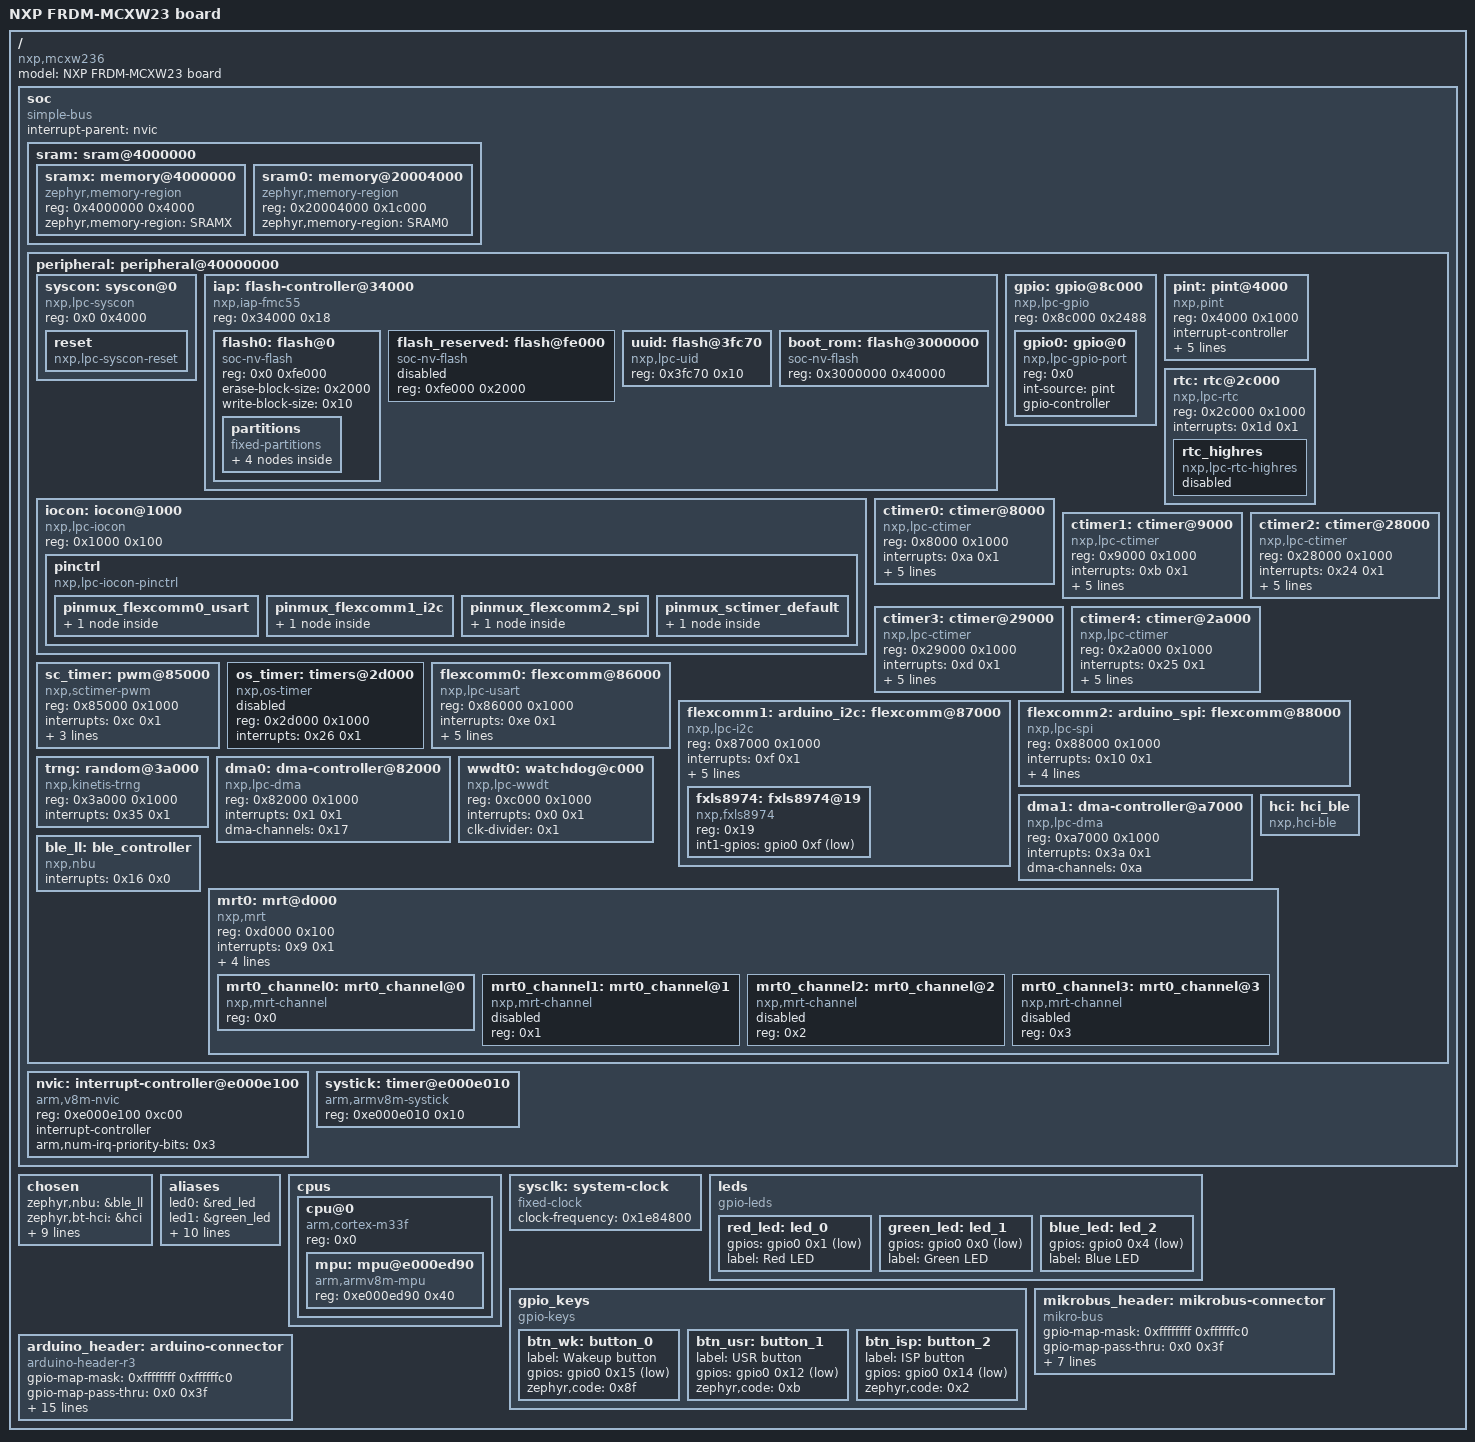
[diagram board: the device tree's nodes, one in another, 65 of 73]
/dts-v1/;

/* node '/' defined in zephyr/dts/arm/nxp/nxp_mcxw236_ns.dtsi:7 */
/ {
	#address-cells = < 0x1 >;        /* in zephyr/dts/common/skeleton.dtsi:10 */
	#size-cells = < 0x1 >;           /* in zephyr/dts/common/skeleton.dtsi:11 */
	model = "NXP FRDM-MCXW23 board"; /* in zephyr/boards/nxp/frdm_mcxw23/frdm_mcxw23.dts:13 */
	compatible = "nxp,mcxw236",
	             "nxp,mcx";          /* in zephyr/boards/nxp/frdm_mcxw23/frdm_mcxw23.dts:14 */

	/* node '/soc' defined in zephyr/dts/arm/nxp/nxp_mcxw236_ns.dtsi:8 */
	soc {
		#address-cells = < 0x1 >;     /* in zephyr/dts/arm/armv8-m.dtsi:7 */
		#size-cells = < 0x1 >;        /* in zephyr/dts/arm/armv8-m.dtsi:8 */
		compatible = "simple-bus";    /* in zephyr/dts/arm/armv8-m.dtsi:9 */
		interrupt-parent = < &nvic >; /* in zephyr/dts/arm/armv8-m.dtsi:10 */
		ranges;                       /* in zephyr/dts/arm/armv8-m.dtsi:11 */

		/* node '/soc/sram@4000000' defined in zephyr/dts/arm/nxp/nxp_mcxw236_ns.dtsi:9 */
		sram: sram@4000000 {
			ranges = < 0x4000000 0x4000000 0x20004000 >; /* in zephyr/dts/arm/nxp/nxp_mcxw236_ns.dtsi:10 */
			#address-cells = < 0x1 >;                    /* in zephyr/dts/arm/nxp/nxp_mcxw23x_common.dtsi:51 */
			#size-cells = < 0x1 >;                       /* in zephyr/dts/arm/nxp/nxp_mcxw23x_common.dtsi:52 */

			/* node '/soc/sram@4000000/memory@4000000' defined in zephyr/dts/arm/nxp/nxp_mcxw23x_common.dtsi:54 */
			sramx: memory@4000000 {
				compatible = "zephyr,memory-region",
				             "mmio-sram";            /* in zephyr/dts/arm/nxp/nxp_mcxw23x_common.dtsi:55 */
				reg = < 0x4000000 0x4000 >;          /* in zephyr/dts/arm/nxp/nxp_mcxw23x_common.dtsi:56 */
				zephyr,memory-region = "SRAMX";      /* in zephyr/dts/arm/nxp/nxp_mcxw23x_common.dtsi:57 */
			};

			/* node '/soc/sram@4000000/memory@20004000' defined in zephyr/dts/arm/nxp/nxp_mcxw23x_common.dtsi:60 */
			sram0: memory@20004000 {
				compatible = "zephyr,memory-region",
				             "mmio-sram";            /* in zephyr/dts/arm/nxp/nxp_mcxw23x_common.dtsi:61 */
				reg = < 0x20004000 0x1c000 >;        /* in zephyr/dts/arm/nxp/nxp_mcxw23x_common.dtsi:62 */
				zephyr,memory-region = "SRAM0";      /* in zephyr/dts/arm/nxp/nxp_mcxw23x_common.dtsi:63 */
			};
		};

		/* node '/soc/peripheral@40000000' defined in zephyr/dts/arm/nxp/nxp_mcxw236_ns.dtsi:13 */
		peripheral: peripheral@40000000 {
			ranges = < 0x0 0x40000000 0x10000000 >; /* in zephyr/dts/arm/nxp/nxp_mcxw236_ns.dtsi:14 */
			#address-cells = < 0x1 >;               /* in zephyr/dts/arm/nxp/nxp_mcxw23x_common.dtsi:72 */
			#size-cells = < 0x1 >;                  /* in zephyr/dts/arm/nxp/nxp_mcxw23x_common.dtsi:73 */

			/* node '/soc/peripheral@40000000/syscon@0' defined in zephyr/dts/arm/nxp/nxp_mcxw23x_common.dtsi:75 */
			syscon: syscon@0 {
				compatible = "nxp,lpc-syscon"; /* in zephyr/dts/arm/nxp/nxp_mcxw23x_common.dtsi:76 */
				reg = < 0x0 0x4000 >;          /* in zephyr/dts/arm/nxp/nxp_mcxw23x_common.dtsi:77 */
				#clock-cells = < 0x1 >;        /* in zephyr/dts/arm/nxp/nxp_mcxw23x_common.dtsi:78 */
				phandle = < 0x2 >;             /* in zephyr/dts/arm/nxp/nxp_mcxw23x_common.dtsi:174 */

				/* node '/soc/peripheral@40000000/syscon@0/reset' defined in zephyr/dts/arm/nxp/nxp_mcxw23x_common.dtsi:80 */
				reset: reset {
					compatible = "nxp,lpc-syscon-reset"; /* in zephyr/dts/arm/nxp/nxp_mcxw23x_common.dtsi:81 */
					#reset-cells = < 0x1 >;              /* in zephyr/dts/arm/nxp/nxp_mcxw23x_common.dtsi:82 */
					phandle = < 0x4 >;                   /* in zephyr/dts/arm/nxp/nxp_mcxw23x_common.dtsi:250 */
				};
			};

			/* node '/soc/peripheral@40000000/flash-controller@34000' defined in zephyr/dts/arm/nxp/nxp_mcxw23x_common.dtsi:86 */
			iap: flash-controller@34000 {
				compatible = "nxp,iap-fmc55"; /* in zephyr/dts/arm/nxp/nxp_mcxw23x_common.dtsi:87 */
				reg = < 0x34000 0x18 >;       /* in zephyr/dts/arm/nxp/nxp_mcxw23x_common.dtsi:88 */
				#address-cells = < 0x1 >;     /* in zephyr/dts/arm/nxp/nxp_mcxw23x_common.dtsi:89 */
				#size-cells = < 0x1 >;        /* in zephyr/dts/arm/nxp/nxp_mcxw23x_common.dtsi:90 */
				status = "okay";              /* in zephyr/dts/arm/nxp/nxp_mcxw23x_common.dtsi:91 */

				/* node '/soc/peripheral@40000000/flash-controller@34000/flash@0' defined in zephyr/dts/arm/nxp/nxp_mcxw23x_common.dtsi:93 */
				flash0: flash@0 {
					compatible = "soc-nv-flash";   /* in zephyr/dts/arm/nxp/nxp_mcxw23x_common.dtsi:94 */
					reg = < 0x0 0xfe000 >;         /* in zephyr/dts/arm/nxp/nxp_mcxw23x_common.dtsi:95 */
					erase-block-size = < 0x2000 >; /* in zephyr/dts/arm/nxp/nxp_mcxw23x_common.dtsi:96 */
					write-block-size = < 0x10 >;   /* in zephyr/dts/arm/nxp/nxp_mcxw23x_common.dtsi:97 */

					/* node '/soc/peripheral@40000000/flash-controller@34000/flash@0/partitions' defined in zephyr/boards/nxp/frdm_mcxw23/frdm_mcxw23_common.dtsi:209 */
					partitions {
						compatible = "fixed-partitions"; /* in zephyr/boards/nxp/frdm_mcxw23/frdm_mcxw23_common.dtsi:210 */
						#address-cells = < 0x1 >;        /* in zephyr/boards/nxp/frdm_mcxw23/frdm_mcxw23_common.dtsi:211 */
						#size-cells = < 0x1 >;           /* in zephyr/boards/nxp/frdm_mcxw23/frdm_mcxw23_common.dtsi:212 */

						/* node '/soc/peripheral@40000000/flash-controller@34000/flash@0/partitions/partition@0' defined in zephyr/boards/nxp/frdm_mcxw23/frdm_mcxw23_common.dtsi:214 */
						boot_partition: partition@0 {
							label = "mcuboot";     /* in zephyr/boards/nxp/frdm_mcxw23/frdm_mcxw23_common.dtsi:215 */
							reg = < 0x0 0x14000 >; /* in zephyr/boards/nxp/frdm_mcxw23/frdm_mcxw23_common.dtsi:216 */
						};

						/* node '/soc/peripheral@40000000/flash-controller@34000/flash@0/partitions/partition@14000' defined in zephyr/boards/nxp/frdm_mcxw23/frdm_mcxw23_common.dtsi:219 */
						slot0_partition: partition@14000 {
							label = "image-0";         /* in zephyr/boards/nxp/frdm_mcxw23/frdm_mcxw23_common.dtsi:220 */
							reg = < 0x14000 0x6e000 >; /* in zephyr/boards/nxp/frdm_mcxw23/frdm_mcxw23_common.dtsi:221 */
						};

						/* node '/soc/peripheral@40000000/flash-controller@34000/flash@0/partitions/partition@82000' defined in zephyr/boards/nxp/frdm_mcxw23/frdm_mcxw23_common.dtsi:224 */
						slot1_partition: partition@82000 {
							label = "image-1";         /* in zephyr/boards/nxp/frdm_mcxw23/frdm_mcxw23_common.dtsi:225 */
							reg = < 0x82000 0x6e000 >; /* in zephyr/boards/nxp/frdm_mcxw23/frdm_mcxw23_common.dtsi:226 */
						};

						/* node '/soc/peripheral@40000000/flash-controller@34000/flash@0/partitions/partition@f0000' defined in zephyr/boards/nxp/frdm_mcxw23/frdm_mcxw23_common.dtsi:229 */
						storage_partition: partition@f0000 {
							label = "storage";        /* in zephyr/boards/nxp/frdm_mcxw23/frdm_mcxw23_common.dtsi:230 */
							reg = < 0xf0000 0xe000 >; /* in zephyr/boards/nxp/frdm_mcxw23/frdm_mcxw23_common.dtsi:231 */
						};
					};
				};

				/* node '/soc/peripheral@40000000/flash-controller@34000/flash@fe000' defined in zephyr/dts/arm/nxp/nxp_mcxw23x_common.dtsi:100 */
				flash_reserved: flash@fe000 {
					compatible = "soc-nv-flash"; /* in zephyr/dts/arm/nxp/nxp_mcxw23x_common.dtsi:101 */
					reg = < 0xfe000 0x2000 >;    /* in zephyr/dts/arm/nxp/nxp_mcxw23x_common.dtsi:102 */
					status = "disabled";         /* in zephyr/dts/arm/nxp/nxp_mcxw23x_common.dtsi:103 */
				};

				/* node '/soc/peripheral@40000000/flash-controller@34000/flash@3fc70' defined in zephyr/dts/arm/nxp/nxp_mcxw23x_common.dtsi:106 */
				uuid: flash@3fc70 {
					compatible = "nxp,lpc-uid"; /* in zephyr/dts/arm/nxp/nxp_mcxw23x_common.dtsi:107 */
					reg = < 0x3fc70 0x10 >;     /* in zephyr/dts/arm/nxp/nxp_mcxw23x_common.dtsi:108 */
				};

				/* node '/soc/peripheral@40000000/flash-controller@34000/flash@3000000' defined in zephyr/dts/arm/nxp/nxp_mcxw23x_common.dtsi:111 */
				boot_rom: flash@3000000 {
					compatible = "soc-nv-flash"; /* in zephyr/dts/arm/nxp/nxp_mcxw23x_common.dtsi:112 */
					reg = < 0x3000000 0x40000 >; /* in zephyr/dts/arm/nxp/nxp_mcxw23x_common.dtsi:113 */
				};
			};

			/* node '/soc/peripheral@40000000/iocon@1000' defined in zephyr/dts/arm/nxp/nxp_mcxw23x_common.dtsi:117 */
			iocon: iocon@1000 {
				compatible = "nxp,lpc-iocon";  /* in zephyr/dts/arm/nxp/nxp_mcxw23x_common.dtsi:118 */
				reg = < 0x1000 0x100 >;        /* in zephyr/dts/arm/nxp/nxp_mcxw23x_common.dtsi:119 */
				#address-cells = < 0x1 >;      /* in zephyr/dts/arm/nxp/nxp_mcxw23x_common.dtsi:120 */
				#size-cells = < 0x1 >;         /* in zephyr/dts/arm/nxp/nxp_mcxw23x_common.dtsi:121 */
				ranges = < 0x0 0x1000 0x100 >; /* in zephyr/dts/arm/nxp/nxp_mcxw23x_common.dtsi:122 */

				/* node '/soc/peripheral@40000000/iocon@1000/pinctrl' defined in zephyr/dts/arm/nxp/nxp_mcxw23x_common.dtsi:124 */
				pinctrl: pinctrl {
					compatible = "nxp,lpc-iocon-pinctrl"; /* in zephyr/dts/arm/nxp/nxp_mcxw23x_common.dtsi:125 */

					/* node '/soc/peripheral@40000000/iocon@1000/pinctrl/pinmux_flexcomm0_usart' defined in zephyr/boards/nxp/frdm_mcxw23/frdm_mcxw23-pinctrl.dtsi:11 */
					pinmux_flexcomm0_usart: pinmux_flexcomm0_usart {
						phandle = < 0x6 >; /* in zephyr/boards/nxp/frdm_mcxw23/frdm_mcxw23_common.dtsi:132 */

						/* node '/soc/peripheral@40000000/iocon@1000/pinctrl/pinmux_flexcomm0_usart/group0' defined in zephyr/boards/nxp/frdm_mcxw23/frdm_mcxw23-pinctrl.dtsi:12 */
						group0 {
							pinmux = < 0x200001 >,
							         < 0x300001 >;  /* in zephyr/boards/nxp/frdm_mcxw23/frdm_mcxw23-pinctrl.dtsi:13 */
							slew-rate = "standard"; /* in zephyr/boards/nxp/frdm_mcxw23/frdm_mcxw23-pinctrl.dtsi:15 */
						};
					};

					/* node '/soc/peripheral@40000000/iocon@1000/pinctrl/pinmux_flexcomm1_i2c' defined in zephyr/boards/nxp/frdm_mcxw23/frdm_mcxw23-pinctrl.dtsi:20 */
					pinmux_flexcomm1_i2c: pinmux_flexcomm1_i2c {
						phandle = < 0x7 >; /* in zephyr/boards/nxp/frdm_mcxw23/frdm_mcxw23_common.dtsi:142 */

						/* node '/soc/peripheral@40000000/iocon@1000/pinctrl/pinmux_flexcomm1_i2c/group0' defined in zephyr/boards/nxp/frdm_mcxw23/frdm_mcxw23-pinctrl.dtsi:21 */
						group0 {
							pinmux = < 0xd40001 >,
							         < 0xe40001 >;  /* in zephyr/boards/nxp/frdm_mcxw23/frdm_mcxw23-pinctrl.dtsi:22 */
							slew-rate = "standard"; /* in zephyr/boards/nxp/frdm_mcxw23/frdm_mcxw23-pinctrl.dtsi:24 */
							power-source = "3v3";   /* in zephyr/boards/nxp/frdm_mcxw23/frdm_mcxw23-pinctrl.dtsi:25 */
						};
					};

					/* node '/soc/peripheral@40000000/iocon@1000/pinctrl/pinmux_flexcomm2_spi' defined in zephyr/boards/nxp/frdm_mcxw23/frdm_mcxw23-pinctrl.dtsi:29 */
					pinmux_flexcomm2_spi: pinmux_flexcomm2_spi {
						phandle = < 0x9 >; /* in zephyr/boards/nxp/frdm_mcxw23/frdm_mcxw23_common.dtsi:241 */

						/* node '/soc/peripheral@40000000/iocon@1000/pinctrl/pinmux_flexcomm2_spi/group0' defined in zephyr/boards/nxp/frdm_mcxw23/frdm_mcxw23-pinctrl.dtsi:30 */
						group0 {
							pinmux = < 0x600002 >,
							         < 0x700002 >,
							         < 0xa00002 >,
							         < 0x500002 >;  /* in zephyr/boards/nxp/frdm_mcxw23/frdm_mcxw23-pinctrl.dtsi:31 */
							slew-rate = "standard"; /* in zephyr/boards/nxp/frdm_mcxw23/frdm_mcxw23-pinctrl.dtsi:35 */
						};
					};

					/* node '/soc/peripheral@40000000/iocon@1000/pinctrl/pinmux_sctimer_default' defined in zephyr/boards/nxp/frdm_mcxw23/frdm_mcxw23-pinctrl.dtsi:39 */
					pinmux_sctimer_default: pinmux_sctimer_default {
						phandle = < 0x3 >; /* in zephyr/boards/nxp/frdm_mcxw23/frdm_mcxw23_common.dtsi:175 */

						/* node '/soc/peripheral@40000000/iocon@1000/pinctrl/pinmux_sctimer_default/group0' defined in zephyr/boards/nxp/frdm_mcxw23/frdm_mcxw23-pinctrl.dtsi:40 */
						group0 {
							pinmux = < 0xf00003 >;  /* in zephyr/boards/nxp/frdm_mcxw23/frdm_mcxw23-pinctrl.dtsi:41 */
							slew-rate = "standard"; /* in zephyr/boards/nxp/frdm_mcxw23/frdm_mcxw23-pinctrl.dtsi:42 */
						};
					};
				};
			};

			/* node '/soc/peripheral@40000000/gpio@8c000' defined in zephyr/dts/arm/nxp/nxp_mcxw23x_common.dtsi:129 */
			gpio: gpio@8c000 {
				compatible = "nxp,lpc-gpio"; /* in zephyr/dts/arm/nxp/nxp_mcxw23x_common.dtsi:130 */
				reg = < 0x8c000 0x2488 >;    /* in zephyr/dts/arm/nxp/nxp_mcxw23x_common.dtsi:131 */
				#address-cells = < 0x1 >;    /* in zephyr/dts/arm/nxp/nxp_mcxw23x_common.dtsi:132 */
				#size-cells = < 0x0 >;       /* in zephyr/dts/arm/nxp/nxp_mcxw23x_common.dtsi:133 */

				/* node '/soc/peripheral@40000000/gpio@8c000/gpio@0' defined in zephyr/dts/arm/nxp/nxp_mcxw23x_common.dtsi:135 */
				gpio0: gpio@0 {
					compatible = "nxp,lpc-gpio-port"; /* in zephyr/dts/arm/nxp/nxp_mcxw23x_common.dtsi:136 */
					reg = < 0x0 >;                    /* in zephyr/dts/arm/nxp/nxp_mcxw23x_common.dtsi:137 */
					int-source = "pint";              /* in zephyr/dts/arm/nxp/nxp_mcxw23x_common.dtsi:138 */
					gpio-controller;                  /* in zephyr/dts/arm/nxp/nxp_mcxw23x_common.dtsi:139 */
					#gpio-cells = < 0x2 >;            /* in zephyr/dts/arm/nxp/nxp_mcxw23x_common.dtsi:140 */
					phandle = < 0x8 >;                /* in zephyr/boards/nxp/frdm_mcxw23/frdm_mcxw23_common.dtsi:149 */
				};
			};

			/* node '/soc/peripheral@40000000/pint@4000' defined in zephyr/dts/arm/nxp/nxp_mcxw23x_common.dtsi:144 */
			pint: pint@4000 {
				compatible = "nxp,pint";    /* in zephyr/dts/arm/nxp/nxp_mcxw23x_common.dtsi:145 */
				reg = < 0x4000 0x1000 >;    /* in zephyr/dts/arm/nxp/nxp_mcxw23x_common.dtsi:146 */
				interrupt-controller;       /* in zephyr/dts/arm/nxp/nxp_mcxw23x_common.dtsi:147 */
				#interrupt-cells = < 0x1 >; /* in zephyr/dts/arm/nxp/nxp_mcxw23x_common.dtsi:148 */
				#address-cells = < 0x0 >;   /* in zephyr/dts/arm/nxp/nxp_mcxw23x_common.dtsi:149 */
				interrupts = < 0x4 0x2 >,
				             < 0x5 0x2 >,
				             < 0x6 0x2 >,
				             < 0x7 0x2 >,
				             < 0x20 0x2 >,
				             < 0x21 0x2 >,
				             < 0x22 0x2 >,
				             < 0x23 0x2 >;  /* in zephyr/dts/arm/nxp/nxp_mcxw23x_common.dtsi:150 */
				num-lines = < 0x8 >;        /* in zephyr/dts/arm/nxp/nxp_mcxw23x_common.dtsi:152 */
				num-inputs = < 0x40 >;      /* in zephyr/dts/arm/nxp/nxp_mcxw23x_common.dtsi:153 */
			};

			/* node '/soc/peripheral@40000000/rtc@2c000' defined in zephyr/dts/arm/nxp/nxp_mcxw23x_common.dtsi:156 */
			rtc: rtc@2c000 {
				compatible = "nxp,lpc-rtc"; /* in zephyr/dts/arm/nxp/nxp_mcxw23x_common.dtsi:157 */
				reg = < 0x2c000 0x1000 >;   /* in zephyr/dts/arm/nxp/nxp_mcxw23x_common.dtsi:158 */
				interrupts = < 0x1d 0x1 >;  /* in zephyr/dts/arm/nxp/nxp_mcxw23x_common.dtsi:159 */
				status = "okay";            /* in zephyr/boards/nxp/frdm_mcxw23/frdm_mcxw23_common.dtsi:193 */

				/* node '/soc/peripheral@40000000/rtc@2c000/rtc_highres' defined in zephyr/dts/arm/nxp/nxp_mcxw23x_common.dtsi:162 */
				rtc_highres: rtc_highres {
					compatible = "nxp,lpc-rtc-highres"; /* in zephyr/dts/arm/nxp/nxp_mcxw23x_common.dtsi:163 */
					status = "disabled";                /* in zephyr/dts/arm/nxp/nxp_mcxw23x_common.dtsi:164 */
				};
			};

			/* node '/soc/peripheral@40000000/ctimer@8000' defined in zephyr/dts/arm/nxp/nxp_mcxw23x_common.dtsi:168 */
			ctimer0: ctimer@8000 {
				compatible = "nxp,lpc-ctimer"; /* in zephyr/dts/arm/nxp/nxp_mcxw23x_common.dtsi:169 */
				reg = < 0x8000 0x1000 >;       /* in zephyr/dts/arm/nxp/nxp_mcxw23x_common.dtsi:170 */
				interrupts = < 0xa 0x1 >;      /* in zephyr/dts/arm/nxp/nxp_mcxw23x_common.dtsi:171 */
				clk-source = < 0x3 >;          /* in zephyr/dts/arm/nxp/nxp_mcxw23x_common.dtsi:173 */
				clocks = < &syscon 0x0 >;      /* in zephyr/dts/arm/nxp/nxp_mcxw23x_common.dtsi:174 */
				mode = < 0x0 >;                /* in zephyr/dts/arm/nxp/nxp_mcxw23x_common.dtsi:175 */
				input = < 0x0 >;               /* in zephyr/dts/arm/nxp/nxp_mcxw23x_common.dtsi:176 */
				prescale = < 0x0 >;            /* in zephyr/dts/arm/nxp/nxp_mcxw23x_common.dtsi:177 */
				status = "okay";               /* in zephyr/boards/nxp/frdm_mcxw23/frdm_mcxw23_common.dtsi:154 */
			};

			/* node '/soc/peripheral@40000000/ctimer@9000' defined in zephyr/dts/arm/nxp/nxp_mcxw23x_common.dtsi:180 */
			ctimer1: ctimer@9000 {
				compatible = "nxp,lpc-ctimer"; /* in zephyr/dts/arm/nxp/nxp_mcxw23x_common.dtsi:181 */
				reg = < 0x9000 0x1000 >;       /* in zephyr/dts/arm/nxp/nxp_mcxw23x_common.dtsi:182 */
				interrupts = < 0xb 0x1 >;      /* in zephyr/dts/arm/nxp/nxp_mcxw23x_common.dtsi:183 */
				clk-source = < 0x3 >;          /* in zephyr/dts/arm/nxp/nxp_mcxw23x_common.dtsi:185 */
				clocks = < &syscon 0x1 >;      /* in zephyr/dts/arm/nxp/nxp_mcxw23x_common.dtsi:186 */
				mode = < 0x0 >;                /* in zephyr/dts/arm/nxp/nxp_mcxw23x_common.dtsi:187 */
				input = < 0x0 >;               /* in zephyr/dts/arm/nxp/nxp_mcxw23x_common.dtsi:188 */
				prescale = < 0x0 >;            /* in zephyr/dts/arm/nxp/nxp_mcxw23x_common.dtsi:189 */
				status = "okay";               /* in zephyr/boards/nxp/frdm_mcxw23/frdm_mcxw23_common.dtsi:158 */
			};

			/* node '/soc/peripheral@40000000/ctimer@28000' defined in zephyr/dts/arm/nxp/nxp_mcxw23x_common.dtsi:192 */
			ctimer2: ctimer@28000 {
				compatible = "nxp,lpc-ctimer"; /* in zephyr/dts/arm/nxp/nxp_mcxw23x_common.dtsi:193 */
				reg = < 0x28000 0x1000 >;      /* in zephyr/dts/arm/nxp/nxp_mcxw23x_common.dtsi:194 */
				interrupts = < 0x24 0x1 >;     /* in zephyr/dts/arm/nxp/nxp_mcxw23x_common.dtsi:195 */
				clk-source = < 0x3 >;          /* in zephyr/dts/arm/nxp/nxp_mcxw23x_common.dtsi:197 */
				clocks = < &syscon 0x2 >;      /* in zephyr/dts/arm/nxp/nxp_mcxw23x_common.dtsi:198 */
				mode = < 0x0 >;                /* in zephyr/dts/arm/nxp/nxp_mcxw23x_common.dtsi:199 */
				input = < 0x0 >;               /* in zephyr/dts/arm/nxp/nxp_mcxw23x_common.dtsi:200 */
				prescale = < 0x0 >;            /* in zephyr/dts/arm/nxp/nxp_mcxw23x_common.dtsi:201 */
				status = "okay";               /* in zephyr/boards/nxp/frdm_mcxw23/frdm_mcxw23_common.dtsi:162 */
			};

			/* node '/soc/peripheral@40000000/ctimer@29000' defined in zephyr/dts/arm/nxp/nxp_mcxw23x_common.dtsi:204 */
			ctimer3: ctimer@29000 {
				compatible = "nxp,lpc-ctimer"; /* in zephyr/dts/arm/nxp/nxp_mcxw23x_common.dtsi:205 */
				reg = < 0x29000 0x1000 >;      /* in zephyr/dts/arm/nxp/nxp_mcxw23x_common.dtsi:206 */
				interrupts = < 0xd 0x1 >;      /* in zephyr/dts/arm/nxp/nxp_mcxw23x_common.dtsi:207 */
				clk-source = < 0x3 >;          /* in zephyr/dts/arm/nxp/nxp_mcxw23x_common.dtsi:209 */
				clocks = < &syscon 0x3 >;      /* in zephyr/dts/arm/nxp/nxp_mcxw23x_common.dtsi:210 */
				mode = < 0x0 >;                /* in zephyr/dts/arm/nxp/nxp_mcxw23x_common.dtsi:211 */
				input = < 0x0 >;               /* in zephyr/dts/arm/nxp/nxp_mcxw23x_common.dtsi:212 */
				prescale = < 0x0 >;            /* in zephyr/dts/arm/nxp/nxp_mcxw23x_common.dtsi:213 */
				status = "okay";               /* in zephyr/boards/nxp/frdm_mcxw23/frdm_mcxw23_common.dtsi:166 */
			};

			/* node '/soc/peripheral@40000000/ctimer@2a000' defined in zephyr/dts/arm/nxp/nxp_mcxw23x_common.dtsi:216 */
			ctimer4: ctimer@2a000 {
				compatible = "nxp,lpc-ctimer"; /* in zephyr/dts/arm/nxp/nxp_mcxw23x_common.dtsi:217 */
				reg = < 0x2a000 0x1000 >;      /* in zephyr/dts/arm/nxp/nxp_mcxw23x_common.dtsi:218 */
				interrupts = < 0x25 0x1 >;     /* in zephyr/dts/arm/nxp/nxp_mcxw23x_common.dtsi:219 */
				clk-source = < 0x3 >;          /* in zephyr/dts/arm/nxp/nxp_mcxw23x_common.dtsi:221 */
				clocks = < &syscon 0x4 >;      /* in zephyr/dts/arm/nxp/nxp_mcxw23x_common.dtsi:222 */
				mode = < 0x0 >;                /* in zephyr/dts/arm/nxp/nxp_mcxw23x_common.dtsi:223 */
				input = < 0x0 >;               /* in zephyr/dts/arm/nxp/nxp_mcxw23x_common.dtsi:224 */
				prescale = < 0x0 >;            /* in zephyr/dts/arm/nxp/nxp_mcxw23x_common.dtsi:225 */
				status = "okay";               /* in zephyr/boards/nxp/frdm_mcxw23/frdm_mcxw23_common.dtsi:170 */
			};

			/* node '/soc/peripheral@40000000/pwm@85000' defined in zephyr/dts/arm/nxp/nxp_mcxw23x_common.dtsi:228 */
			sc_timer: pwm@85000 {
				compatible = "nxp,sctimer-pwm";          /* in zephyr/dts/arm/nxp/nxp_mcxw23x_common.dtsi:229 */
				reg = < 0x85000 0x1000 >;                /* in zephyr/dts/arm/nxp/nxp_mcxw23x_common.dtsi:230 */
				interrupts = < 0xc 0x1 >;                /* in zephyr/dts/arm/nxp/nxp_mcxw23x_common.dtsi:231 */
				clocks = < &syscon 0x900 >;              /* in zephyr/dts/arm/nxp/nxp_mcxw23x_common.dtsi:233 */
				prescaler = < 0x2 >;                     /* in zephyr/dts/arm/nxp/nxp_mcxw23x_common.dtsi:234 */
				#pwm-cells = < 0x3 >;                    /* in zephyr/dts/arm/nxp/nxp_mcxw23x_common.dtsi:235 */
				status = "okay";                         /* in zephyr/boards/nxp/frdm_mcxw23/frdm_mcxw23_common.dtsi:174 */
				pinctrl-0 = < &pinmux_sctimer_default >; /* in zephyr/boards/nxp/frdm_mcxw23/frdm_mcxw23_common.dtsi:175 */
				pinctrl-names = "default";               /* in zephyr/boards/nxp/frdm_mcxw23/frdm_mcxw23_common.dtsi:176 */
			};

			/* node '/soc/peripheral@40000000/timers@2d000' defined in zephyr/dts/arm/nxp/nxp_mcxw23x_common.dtsi:238 */
			os_timer: timers@2d000 {
				compatible = "nxp,os-timer"; /* in zephyr/dts/arm/nxp/nxp_mcxw23x_common.dtsi:239 */
				reg = < 0x2d000 0x1000 >;    /* in zephyr/dts/arm/nxp/nxp_mcxw23x_common.dtsi:240 */
				interrupts = < 0x26 0x1 >;   /* in zephyr/dts/arm/nxp/nxp_mcxw23x_common.dtsi:241 */
				status = "disabled";         /* in zephyr/dts/arm/nxp/nxp_mcxw23x_common.dtsi:242 */
			};

			/* node '/soc/peripheral@40000000/flexcomm@86000' defined in zephyr/dts/arm/nxp/nxp_mcxw23x_common.dtsi:245 */
			flexcomm0: flexcomm@86000 {
				reg = < 0x86000 0x1000 >;                /* in zephyr/dts/arm/nxp/nxp_mcxw23x_common.dtsi:247 */
				interrupts = < 0xe 0x1 >;                /* in zephyr/dts/arm/nxp/nxp_mcxw23x_common.dtsi:248 */
				clocks = < &syscon 0x100 >;              /* in zephyr/dts/arm/nxp/nxp_mcxw23x_common.dtsi:249 */
				resets = < &reset 0x1000b >;             /* in zephyr/dts/arm/nxp/nxp_mcxw23x_common.dtsi:250 */
				dmas = < &dma0 0x4 &dma0 0x5 >;          /* in zephyr/dts/arm/nxp/nxp_mcxw23x_common.dtsi:251 */
				dma-names = "rx",
				            "tx";                        /* in zephyr/dts/arm/nxp/nxp_mcxw23x_common.dtsi:252 */
				status = "okay";                         /* in zephyr/boards/nxp/frdm_mcxw23/frdm_mcxw23_common.dtsi:129 */
				compatible = "nxp,lpc-usart";            /* in zephyr/boards/nxp/frdm_mcxw23/frdm_mcxw23_common.dtsi:130 */
				current-speed = < 0x1c200 >;             /* in zephyr/boards/nxp/frdm_mcxw23/frdm_mcxw23_common.dtsi:131 */
				pinctrl-0 = < &pinmux_flexcomm0_usart >; /* in zephyr/boards/nxp/frdm_mcxw23/frdm_mcxw23_common.dtsi:132 */
				pinctrl-names = "default";               /* in zephyr/boards/nxp/frdm_mcxw23/frdm_mcxw23_common.dtsi:133 */
			};

			/* node '/soc/peripheral@40000000/flexcomm@87000' defined in zephyr/dts/arm/nxp/nxp_mcxw23x_common.dtsi:256 */
			flexcomm1: arduino_i2c: mikrobus_i2c: flexcomm@87000 {
				reg = < 0x87000 0x1000 >;              /* in zephyr/dts/arm/nxp/nxp_mcxw23x_common.dtsi:258 */
				interrupts = < 0xf 0x1 >;              /* in zephyr/dts/arm/nxp/nxp_mcxw23x_common.dtsi:259 */
				clocks = < &syscon 0x101 >;            /* in zephyr/dts/arm/nxp/nxp_mcxw23x_common.dtsi:260 */
				resets = < &reset 0x1000c >;           /* in zephyr/dts/arm/nxp/nxp_mcxw23x_common.dtsi:261 */
				dmas = < &dma0 0x6 &dma0 0x7 >;        /* in zephyr/dts/arm/nxp/nxp_mcxw23x_common.dtsi:262 */
				dma-names = "rx",
				            "tx";                      /* in zephyr/dts/arm/nxp/nxp_mcxw23x_common.dtsi:263 */
				status = "okay";                       /* in zephyr/boards/nxp/frdm_mcxw23/frdm_mcxw23_common.dtsi:137 */
				compatible = "nxp,lpc-i2c";            /* in zephyr/boards/nxp/frdm_mcxw23/frdm_mcxw23_common.dtsi:138 */
				clock-frequency = < 0x186a0 >;         /* in zephyr/boards/nxp/frdm_mcxw23/frdm_mcxw23_common.dtsi:139 */
				#address-cells = < 0x1 >;              /* in zephyr/boards/nxp/frdm_mcxw23/frdm_mcxw23_common.dtsi:140 */
				#size-cells = < 0x0 >;                 /* in zephyr/boards/nxp/frdm_mcxw23/frdm_mcxw23_common.dtsi:141 */
				pinctrl-0 = < &pinmux_flexcomm1_i2c >; /* in zephyr/boards/nxp/frdm_mcxw23/frdm_mcxw23_common.dtsi:142 */
				pinctrl-names = "default";             /* in zephyr/boards/nxp/frdm_mcxw23/frdm_mcxw23_common.dtsi:143 */

				/* node '/soc/peripheral@40000000/flexcomm@87000/fxls8974@19' defined in zephyr/boards/nxp/frdm_mcxw23/frdm_mcxw23_common.dtsi:145 */
				fxls8974: fxls8974@19 {
					compatible = "nxp,fxls8974";     /* in zephyr/boards/nxp/frdm_mcxw23/frdm_mcxw23_common.dtsi:146 */
					reg = < 0x19 >;                  /* in zephyr/boards/nxp/frdm_mcxw23/frdm_mcxw23_common.dtsi:147 */
					status = "okay";                 /* in zephyr/boards/nxp/frdm_mcxw23/frdm_mcxw23_common.dtsi:148 */
					int1-gpios = < &gpio0 0xf 0x1 >; /* in zephyr/boards/nxp/frdm_mcxw23/frdm_mcxw23_common.dtsi:149 */
				};
			};

			/* node '/soc/peripheral@40000000/flexcomm@88000' defined in zephyr/dts/arm/nxp/nxp_mcxw23x_common.dtsi:267 */
			flexcomm2: arduino_spi: mikrobus_spi: flexcomm@88000 {
				reg = < 0x88000 0x1000 >;              /* in zephyr/dts/arm/nxp/nxp_mcxw23x_common.dtsi:269 */
				interrupts = < 0x10 0x1 >;             /* in zephyr/dts/arm/nxp/nxp_mcxw23x_common.dtsi:270 */
				clocks = < &syscon 0x102 >;            /* in zephyr/dts/arm/nxp/nxp_mcxw23x_common.dtsi:271 */
				resets = < &reset 0x1000d >;           /* in zephyr/dts/arm/nxp/nxp_mcxw23x_common.dtsi:272 */
				dmas = < &dma0 0x8 &dma0 0x9 >;        /* in zephyr/dts/arm/nxp/nxp_mcxw23x_common.dtsi:273 */
				dma-names = "rx",
				            "tx";                      /* in zephyr/dts/arm/nxp/nxp_mcxw23x_common.dtsi:274 */
				status = "okay";                       /* in zephyr/boards/nxp/frdm_mcxw23/frdm_mcxw23_common.dtsi:239 */
				compatible = "nxp,lpc-spi";            /* in zephyr/boards/nxp/frdm_mcxw23/frdm_mcxw23_common.dtsi:240 */
				pinctrl-0 = < &pinmux_flexcomm2_spi >; /* in zephyr/boards/nxp/frdm_mcxw23/frdm_mcxw23_common.dtsi:241 */
				pinctrl-names = "default";             /* in zephyr/boards/nxp/frdm_mcxw23/frdm_mcxw23_common.dtsi:242 */
				#address-cells = < 0x1 >;              /* in zephyr/boards/nxp/frdm_mcxw23/frdm_mcxw23_common.dtsi:243 */
				#size-cells = < 0x0 >;                 /* in zephyr/boards/nxp/frdm_mcxw23/frdm_mcxw23_common.dtsi:244 */
			};

			/* node '/soc/peripheral@40000000/random@3a000' defined in zephyr/dts/arm/nxp/nxp_mcxw23x_common.dtsi:278 */
			trng: random@3a000 {
				compatible = "nxp,kinetis-trng"; /* in zephyr/dts/arm/nxp/nxp_mcxw23x_common.dtsi:279 */
				reg = < 0x3a000 0x1000 >;        /* in zephyr/dts/arm/nxp/nxp_mcxw23x_common.dtsi:280 */
				status = "okay";                 /* in zephyr/dts/arm/nxp/nxp_mcxw23x_common.dtsi:281 */
				interrupts = < 0x35 0x1 >;       /* in zephyr/dts/arm/nxp/nxp_mcxw23x_common.dtsi:282 */
			};

			/* node '/soc/peripheral@40000000/dma-controller@82000' defined in zephyr/dts/arm/nxp/nxp_mcxw23x_common.dtsi:285 */
			dma0: dma-controller@82000 {
				compatible = "nxp,lpc-dma"; /* in zephyr/dts/arm/nxp/nxp_mcxw23x_common.dtsi:286 */
				reg = < 0x82000 0x1000 >;   /* in zephyr/dts/arm/nxp/nxp_mcxw23x_common.dtsi:287 */
				interrupts = < 0x1 0x1 >;   /* in zephyr/dts/arm/nxp/nxp_mcxw23x_common.dtsi:288 */
				dma-channels = < 0x17 >;    /* in zephyr/dts/arm/nxp/nxp_mcxw23x_common.dtsi:289 */
				#dma-cells = < 0x1 >;       /* in zephyr/dts/arm/nxp/nxp_mcxw23x_common.dtsi:291 */
				status = "okay";            /* in zephyr/boards/nxp/frdm_mcxw23/frdm_mcxw23_common.dtsi:201 */
				phandle = < 0x5 >;          /* in zephyr/dts/arm/nxp/nxp_mcxw23x_common.dtsi:251 */
			};

			/* node '/soc/peripheral@40000000/dma-controller@a7000' defined in zephyr/dts/arm/nxp/nxp_mcxw23x_common.dtsi:294 */
			dma1: dma-controller@a7000 {
				compatible = "nxp,lpc-dma"; /* in zephyr/dts/arm/nxp/nxp_mcxw23x_common.dtsi:295 */
				reg = < 0xa7000 0x1000 >;   /* in zephyr/dts/arm/nxp/nxp_mcxw23x_common.dtsi:296 */
				interrupts = < 0x3a 0x1 >;  /* in zephyr/dts/arm/nxp/nxp_mcxw23x_common.dtsi:297 */
				dma-channels = < 0xa >;     /* in zephyr/dts/arm/nxp/nxp_mcxw23x_common.dtsi:298 */
				#dma-cells = < 0x1 >;       /* in zephyr/dts/arm/nxp/nxp_mcxw23x_common.dtsi:300 */
				status = "okay";            /* in zephyr/boards/nxp/frdm_mcxw23/frdm_mcxw23_common.dtsi:205 */
			};

			/* node '/soc/peripheral@40000000/watchdog@c000' defined in zephyr/dts/arm/nxp/nxp_mcxw23x_common.dtsi:303 */
			wwdt0: watchdog@c000 {
				compatible = "nxp,lpc-wwdt"; /* in zephyr/dts/arm/nxp/nxp_mcxw23x_common.dtsi:304 */
				reg = < 0xc000 0x1000 >;     /* in zephyr/dts/arm/nxp/nxp_mcxw23x_common.dtsi:305 */
				interrupts = < 0x0 0x1 >;    /* in zephyr/dts/arm/nxp/nxp_mcxw23x_common.dtsi:306 */
				clk-divider = < 0x1 >;       /* in zephyr/dts/arm/nxp/nxp_mcxw23x_common.dtsi:308 */
				status = "okay";             /* in zephyr/boards/nxp/frdm_mcxw23/frdm_mcxw23_common.dtsi:189 */
			};

			/* node '/soc/peripheral@40000000/hci_ble' defined in zephyr/dts/arm/nxp/nxp_mcxw23x_common.dtsi:311 */
			hci: hci_ble {
				compatible = "nxp,hci-ble"; /* in zephyr/dts/arm/nxp/nxp_mcxw23x_common.dtsi:312 */
			};

			/* node '/soc/peripheral@40000000/ble_controller' defined in zephyr/dts/arm/nxp/nxp_mcxw23x_common.dtsi:315 */
			ble_ll: ble_controller {
				compatible = "nxp,nbu";         /* in zephyr/dts/arm/nxp/nxp_mcxw23x_common.dtsi:316 */
				interrupts = < 0x16 0x0 >;      /* in zephyr/dts/arm/nxp/nxp_mcxw23x_common.dtsi:317 */
				interrupt-names = "nbu_rx_int"; /* in zephyr/dts/arm/nxp/nxp_mcxw23x_common.dtsi:318 */
			};

			/* node '/soc/peripheral@40000000/mrt@d000' defined in zephyr/dts/arm/nxp/nxp_mcxw23x_common.dtsi:321 */
			mrt0: mrt@d000 {
				compatible = "nxp,mrt";      /* in zephyr/dts/arm/nxp/nxp_mcxw23x_common.dtsi:322 */
				reg = < 0xd000 0x100 >;      /* in zephyr/dts/arm/nxp/nxp_mcxw23x_common.dtsi:323 */
				interrupts = < 0x9 0x1 >;    /* in zephyr/dts/arm/nxp/nxp_mcxw23x_common.dtsi:324 */
				num-channels = < 0x4 >;      /* in zephyr/dts/arm/nxp/nxp_mcxw23x_common.dtsi:325 */
				num-bits = < 0x18 >;         /* in zephyr/dts/arm/nxp/nxp_mcxw23x_common.dtsi:326 */
				clocks = < &syscon 0xb00 >;  /* in zephyr/dts/arm/nxp/nxp_mcxw23x_common.dtsi:327 */
				resets = < &reset 0x10000 >; /* in zephyr/dts/arm/nxp/nxp_mcxw23x_common.dtsi:328 */
				#address-cells = < 0x1 >;    /* in zephyr/dts/arm/nxp/nxp_mcxw23x_common.dtsi:329 */
				#size-cells = < 0x0 >;       /* in zephyr/dts/arm/nxp/nxp_mcxw23x_common.dtsi:330 */

				/* node '/soc/peripheral@40000000/mrt@d000/mrt0_channel@0' defined in zephyr/dts/arm/nxp/nxp_mcxw23x_common.dtsi:332 */
				mrt0_channel0: mrt0_channel@0 {
					compatible = "nxp,mrt-channel"; /* in zephyr/dts/arm/nxp/nxp_mcxw23x_common.dtsi:333 */
					reg = < 0x0 >;                  /* in zephyr/dts/arm/nxp/nxp_mcxw23x_common.dtsi:334 */
					status = "okay";                /* in zephyr/boards/nxp/frdm_mcxw23/frdm_mcxw23_common.dtsi:197 */
				};

				/* node '/soc/peripheral@40000000/mrt@d000/mrt0_channel@1' defined in zephyr/dts/arm/nxp/nxp_mcxw23x_common.dtsi:338 */
				mrt0_channel1: mrt0_channel@1 {
					compatible = "nxp,mrt-channel"; /* in zephyr/dts/arm/nxp/nxp_mcxw23x_common.dtsi:339 */
					reg = < 0x1 >;                  /* in zephyr/dts/arm/nxp/nxp_mcxw23x_common.dtsi:340 */
					status = "disabled";            /* in zephyr/dts/arm/nxp/nxp_mcxw23x_common.dtsi:341 */
				};

				/* node '/soc/peripheral@40000000/mrt@d000/mrt0_channel@2' defined in zephyr/dts/arm/nxp/nxp_mcxw23x_common.dtsi:344 */
				mrt0_channel2: mrt0_channel@2 {
					compatible = "nxp,mrt-channel"; /* in zephyr/dts/arm/nxp/nxp_mcxw23x_common.dtsi:345 */
					reg = < 0x2 >;                  /* in zephyr/dts/arm/nxp/nxp_mcxw23x_common.dtsi:346 */
					status = "disabled";            /* in zephyr/dts/arm/nxp/nxp_mcxw23x_common.dtsi:347 */
				};

				/* node '/soc/peripheral@40000000/mrt@d000/mrt0_channel@3' defined in zephyr/dts/arm/nxp/nxp_mcxw23x_common.dtsi:350 */
				mrt0_channel3: mrt0_channel@3 {
					compatible = "nxp,mrt-channel"; /* in zephyr/dts/arm/nxp/nxp_mcxw23x_common.dtsi:351 */
					reg = < 0x3 >;                  /* in zephyr/dts/arm/nxp/nxp_mcxw23x_common.dtsi:352 */
					status = "disabled";            /* in zephyr/dts/arm/nxp/nxp_mcxw23x_common.dtsi:353 */
				};
			};
		};

		/* node '/soc/interrupt-controller@e000e100' defined in zephyr/dts/arm/armv8-m.dtsi:13 */
		nvic: interrupt-controller@e000e100 {
			#address-cells = < 0x1 >;            /* in zephyr/dts/arm/armv8-m.dtsi:14 */
			compatible = "arm,v8m-nvic";         /* in zephyr/dts/arm/armv8-m.dtsi:15 */
			reg = < 0xe000e100 0xc00 >;          /* in zephyr/dts/arm/armv8-m.dtsi:16 */
			interrupt-controller;                /* in zephyr/dts/arm/armv8-m.dtsi:17 */
			#interrupt-cells = < 0x2 >;          /* in zephyr/dts/arm/armv8-m.dtsi:18 */
			arm,num-irq-priority-bits = < 0x3 >; /* in zephyr/dts/arm/nxp/nxp_mcxw23x_common.dtsi:359 */
			phandle = < 0x1 >;                   /* in zephyr/dts/arm/armv8-m.dtsi:10 */
		};

		/* node '/soc/timer@e000e010' defined in zephyr/dts/arm/armv8-m.dtsi:21 */
		systick: timer@e000e010 {
			compatible = "arm,armv8m-systick"; /* in zephyr/dts/arm/armv8-m.dtsi:22 */
			reg = < 0xe000e010 0x10 >;         /* in zephyr/dts/arm/armv8-m.dtsi:23 */
			status = "okay";                   /* in zephyr/boards/nxp/frdm_mcxw23/frdm_mcxw23_common.dtsi:185 */
		};
	};

	/* node '/chosen' defined in zephyr/dts/common/skeleton.dtsi:13 */
	chosen {
		zephyr,nbu = &ble_ll;                     /* in zephyr/dts/arm/nxp/nxp_mcxw23x_common.dtsi:21 */
		zephyr,bt-hci = &hci;                     /* in zephyr/dts/arm/nxp/nxp_mcxw23x_common.dtsi:22 */
		zephyr,entropy = &trng;                   /* in zephyr/dts/arm/nxp/nxp_mcxw23x_common.dtsi:23 */
		zephyr,sram = &sram0;                     /* in zephyr/boards/nxp/frdm_mcxw23/frdm_mcxw23_common.dtsi:13 */
		zephyr,flash = &flash0;                   /* in zephyr/boards/nxp/frdm_mcxw23/frdm_mcxw23_common.dtsi:14 */
		zephyr,code-partition = &slot0_partition; /* in zephyr/boards/nxp/frdm_mcxw23/frdm_mcxw23_common.dtsi:15 */
		zephyr,uart-mcumgr = &flexcomm0;          /* in zephyr/boards/nxp/frdm_mcxw23/frdm_mcxw23_common.dtsi:16 */
		zephyr,console = &flexcomm0;              /* in zephyr/boards/nxp/frdm_mcxw23/frdm_mcxw23_common.dtsi:17 */
		zephyr,shell-uart = &flexcomm0;           /* in zephyr/boards/nxp/frdm_mcxw23/frdm_mcxw23_common.dtsi:18 */
		zephyr,uart-pipe = &flexcomm0;            /* in zephyr/boards/nxp/frdm_mcxw23/frdm_mcxw23_common.dtsi:19 */
		zephyr,flash-controller = &iap;           /* in zephyr/boards/nxp/frdm_mcxw23/frdm_mcxw23_common.dtsi:20 */
	};

	/* node '/aliases' defined in zephyr/dts/common/skeleton.dtsi:15 */
	aliases {
		led0 = &red_led;           /* in zephyr/boards/nxp/frdm_mcxw23/frdm_mcxw23_common.dtsi:24 */
		led1 = &green_led;         /* in zephyr/boards/nxp/frdm_mcxw23/frdm_mcxw23_common.dtsi:25 */
		led2 = &blue_led;          /* in zephyr/boards/nxp/frdm_mcxw23/frdm_mcxw23_common.dtsi:26 */
		sw0 = &btn_wk;             /* in zephyr/boards/nxp/frdm_mcxw23/frdm_mcxw23_common.dtsi:27 */
		sw1 = &btn_usr;            /* in zephyr/boards/nxp/frdm_mcxw23/frdm_mcxw23_common.dtsi:28 */
		sw2 = &btn_isp;            /* in zephyr/boards/nxp/frdm_mcxw23/frdm_mcxw23_common.dtsi:29 */
		usart-0 = &flexcomm0;      /* in zephyr/boards/nxp/frdm_mcxw23/frdm_mcxw23_common.dtsi:30 */
		magn0 = &fxls8974;         /* in zephyr/boards/nxp/frdm_mcxw23/frdm_mcxw23_common.dtsi:31 */
		accel0 = &fxls8974;        /* in zephyr/boards/nxp/frdm_mcxw23/frdm_mcxw23_common.dtsi:32 */
		mcuboot-button0 = &btn_wk; /* in zephyr/boards/nxp/frdm_mcxw23/frdm_mcxw23_common.dtsi:33 */
		watchdog0 = &wwdt0;        /* in zephyr/boards/nxp/frdm_mcxw23/frdm_mcxw23_common.dtsi:34 */
		pwm-0 = &sc_timer;         /* in zephyr/boards/nxp/frdm_mcxw23/frdm_mcxw23_common.dtsi:35 */
	};

	/* node '/cpus' defined in zephyr/dts/arm/nxp/nxp_mcxw23x_common.dtsi:26 */
	cpus {
		#address-cells = < 0x1 >; /* in zephyr/dts/arm/nxp/nxp_mcxw23x_common.dtsi:27 */
		#size-cells = < 0x0 >;    /* in zephyr/dts/arm/nxp/nxp_mcxw23x_common.dtsi:28 */

		/* node '/cpus/cpu@0' defined in zephyr/dts/arm/nxp/nxp_mcxw23x_common.dtsi:30 */
		cpu@0 {
			compatible = "arm,cortex-m33f"; /* in zephyr/dts/arm/nxp/nxp_mcxw23x_common.dtsi:31 */
			reg = < 0x0 >;                  /* in zephyr/dts/arm/nxp/nxp_mcxw23x_common.dtsi:32 */
			#address-cells = < 0x1 >;       /* in zephyr/dts/arm/nxp/nxp_mcxw23x_common.dtsi:33 */
			#size-cells = < 0x1 >;          /* in zephyr/dts/arm/nxp/nxp_mcxw23x_common.dtsi:34 */

			/* node '/cpus/cpu@0/mpu@e000ed90' defined in zephyr/dts/arm/nxp/nxp_mcxw23x_common.dtsi:36 */
			mpu: mpu@e000ed90 {
				compatible = "arm,armv8m-mpu"; /* in zephyr/dts/arm/nxp/nxp_mcxw23x_common.dtsi:37 */
				reg = < 0xe000ed90 0x40 >;     /* in zephyr/dts/arm/nxp/nxp_mcxw23x_common.dtsi:38 */
			};
		};
	};

	/* node '/system-clock' defined in zephyr/dts/arm/nxp/nxp_mcxw23x_common.dtsi:43 */
	sysclk: system-clock {
		compatible = "fixed-clock";      /* in zephyr/dts/arm/nxp/nxp_mcxw23x_common.dtsi:44 */
		clock-frequency = < 0x1e84800 >; /* in zephyr/dts/arm/nxp/nxp_mcxw23x_common.dtsi:45 */
		#clock-cells = < 0x0 >;          /* in zephyr/dts/arm/nxp/nxp_mcxw23x_common.dtsi:46 */
	};

	/* node '/leds' defined in zephyr/boards/nxp/frdm_mcxw23/frdm_mcxw23_common.dtsi:38 */
	leds {
		compatible = "gpio-leds"; /* in zephyr/boards/nxp/frdm_mcxw23/frdm_mcxw23_common.dtsi:39 */

		/* node '/leds/led_0' defined in zephyr/boards/nxp/frdm_mcxw23/frdm_mcxw23_common.dtsi:41 */
		red_led: led_0 {
			gpios = < &gpio0 0x1 0x1 >; /* in zephyr/boards/nxp/frdm_mcxw23/frdm_mcxw23_common.dtsi:42 */
			label = "Red LED";          /* in zephyr/boards/nxp/frdm_mcxw23/frdm_mcxw23_common.dtsi:43 */
		};

		/* node '/leds/led_1' defined in zephyr/boards/nxp/frdm_mcxw23/frdm_mcxw23_common.dtsi:46 */
		green_led: led_1 {
			gpios = < &gpio0 0x0 0x1 >; /* in zephyr/boards/nxp/frdm_mcxw23/frdm_mcxw23_common.dtsi:47 */
			label = "Green LED";        /* in zephyr/boards/nxp/frdm_mcxw23/frdm_mcxw23_common.dtsi:48 */
		};

		/* node '/leds/led_2' defined in zephyr/boards/nxp/frdm_mcxw23/frdm_mcxw23_common.dtsi:51 */
		blue_led: led_2 {
			gpios = < &gpio0 0x4 0x1 >; /* in zephyr/boards/nxp/frdm_mcxw23/frdm_mcxw23_common.dtsi:52 */
			label = "Blue LED";         /* in zephyr/boards/nxp/frdm_mcxw23/frdm_mcxw23_common.dtsi:53 */
		};
	};

	/* node '/gpio_keys' defined in zephyr/boards/nxp/frdm_mcxw23/frdm_mcxw23_common.dtsi:57 */
	gpio_keys {
		compatible = "gpio-keys"; /* in zephyr/boards/nxp/frdm_mcxw23/frdm_mcxw23_common.dtsi:58 */

		/* node '/gpio_keys/button_0' defined in zephyr/boards/nxp/frdm_mcxw23/frdm_mcxw23_common.dtsi:60 */
		btn_wk: button_0 {
			label = "Wakeup button";     /* in zephyr/boards/nxp/frdm_mcxw23/frdm_mcxw23_common.dtsi:61 */
			gpios = < &gpio0 0x15 0x1 >; /* in zephyr/boards/nxp/frdm_mcxw23/frdm_mcxw23_common.dtsi:62 */
			zephyr,code = < 0x8f >;      /* in zephyr/boards/nxp/frdm_mcxw23/frdm_mcxw23_common.dtsi:63 */
		};

		/* node '/gpio_keys/button_1' defined in zephyr/boards/nxp/frdm_mcxw23/frdm_mcxw23_common.dtsi:66 */
		btn_usr: button_1 {
			label = "USR button";        /* in zephyr/boards/nxp/frdm_mcxw23/frdm_mcxw23_common.dtsi:67 */
			gpios = < &gpio0 0x12 0x1 >; /* in zephyr/boards/nxp/frdm_mcxw23/frdm_mcxw23_common.dtsi:68 */
			zephyr,code = < 0xb >;       /* in zephyr/boards/nxp/frdm_mcxw23/frdm_mcxw23_common.dtsi:69 */
		};

		/* node '/gpio_keys/button_2' defined in zephyr/boards/nxp/frdm_mcxw23/frdm_mcxw23_common.dtsi:72 */
		btn_isp: button_2 {
			label = "ISP button";        /* in zephyr/boards/nxp/frdm_mcxw23/frdm_mcxw23_common.dtsi:73 */
			gpios = < &gpio0 0x14 0x1 >; /* in zephyr/boards/nxp/frdm_mcxw23/frdm_mcxw23_common.dtsi:74 */
			zephyr,code = < 0x2 >;       /* in zephyr/boards/nxp/frdm_mcxw23/frdm_mcxw23_common.dtsi:75 */
		};
	};

	/* node '/mikrobus-connector' defined in zephyr/boards/nxp/frdm_mcxw23/frdm_mcxw23_common.dtsi:79 */
	mikrobus_header: mikrobus-connector {
		compatible = "mikro-bus";                  /* in zephyr/boards/nxp/frdm_mcxw23/frdm_mcxw23_common.dtsi:80 */
		#gpio-cells = < 0x2 >;                     /* in zephyr/boards/nxp/frdm_mcxw23/frdm_mcxw23_common.dtsi:81 */
		gpio-map-mask = < 0xffffffff 0xffffffc0 >; /* in zephyr/boards/nxp/frdm_mcxw23/frdm_mcxw23_common.dtsi:82 */
		gpio-map-pass-thru = < 0x0 0x3f >;         /* in zephyr/boards/nxp/frdm_mcxw23/frdm_mcxw23_common.dtsi:83 */
		gpio-map = < 0x2 0x0 &gpio0 0x8 0x0 >,
		           < 0x3 0x0 &gpio0 0xa 0x0 >,
		           < 0x4 0x0 &gpio0 0x7 0x0 >,
		           < 0x5 0x0 &gpio0 0x6 0x0 >,
		           < 0x6 0x0 &gpio0 0xf 0x0 >,
		           < 0x7 0x0 &gpio0 0x10 0x0 >,
		           < 0x8 0x0 &gpio0 0x3 0x0 >,
		           < 0x9 0x0 &gpio0 0x2 0x0 >,
		           < 0xa 0x0 &gpio0 0xe 0x0 >,
		           < 0xb 0x0 &gpio0 0xd 0x0 >;     /* in zephyr/boards/nxp/frdm_mcxw23/frdm_mcxw23_common.dtsi:84 */
	};

	/* node '/arduino-connector' defined in zephyr/boards/nxp/frdm_mcxw23/frdm_mcxw23_common.dtsi:98 */
	arduino_header: arduino-connector {
		compatible = "arduino-header-r3";          /* in zephyr/boards/nxp/frdm_mcxw23/frdm_mcxw23_common.dtsi:99 */
		#gpio-cells = < 0x2 >;                     /* in zephyr/boards/nxp/frdm_mcxw23/frdm_mcxw23_common.dtsi:100 */
		gpio-map-mask = < 0xffffffff 0xffffffc0 >; /* in zephyr/boards/nxp/frdm_mcxw23/frdm_mcxw23_common.dtsi:101 */
		gpio-map-pass-thru = < 0x0 0x3f >;         /* in zephyr/boards/nxp/frdm_mcxw23/frdm_mcxw23_common.dtsi:102 */
		gpio-map = < 0x0 0x0 &gpio0 0x10 0x0 >,
		           < 0x1 0x0 &gpio0 0x13 0x0 >,
		           < 0x2 0x0 &gpio0 0x16 0x0 >,
		           < 0x3 0x0 &gpio0 0x14 0x0 >,
		           < 0x4 0x0 &gpio0 0xd 0x0 >,
		           < 0x5 0x0 &gpio0 0xe 0x0 >,
		           < 0x6 0x0 &gpio0 0x2 0x0 >,
		           < 0x7 0x0 &gpio0 0x3 0x0 >,
		           < 0x8 0x0 &gpio0 0x15 0x0 >,
		           < 0x9 0x0 &gpio0 0x12 0x0 >,
		           < 0xa 0x0 &gpio0 0x0 0x0 >,
		           < 0xb 0x0 &gpio0 0x9 0x0 >,
		           < 0xc 0x0 &gpio0 0x4 0x0 >,
		           < 0xd 0x0 &gpio0 0x1 0x0 >,
		           < 0xe 0x0 &gpio0 0x0 0x0 >,
		           < 0xf 0x0 &gpio0 0xf 0x0 >,
		           < 0x10 0x0 &gpio0 0x8 0x0 >,
		           < 0x11 0x0 &gpio0 0x6 0x0 >,
		           < 0x12 0x0 &gpio0 0x7 0x0 >,
		           < 0x13 0x0 &gpio0 0xa 0x0 >,
		           < 0x14 0x0 &gpio0 0xd 0x0 >,
		           < 0x15 0x0 &gpio0 0xe 0x0 >;    /* in zephyr/boards/nxp/frdm_mcxw23/frdm_mcxw23_common.dtsi:103 */
	};
};
